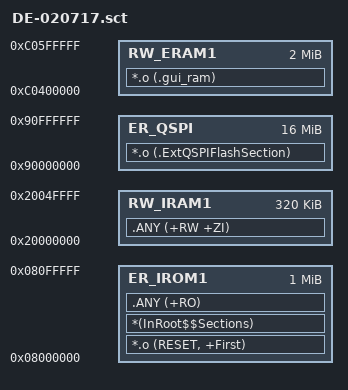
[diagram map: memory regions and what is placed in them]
; *************************************************************
; *** Scatter-Loading Description File generated by uVision ***
; *************************************************************

LR_IROM1 0x08000000 0x00100000    		; load region size_region  
{
	ER_IROM1 0x08000000 0x00100000  	; load address = execution address  
	{
		*.o (RESET, +First)
		*(InRoot$$Sections)
		.ANY (+RO)
	}
	
	RW_IRAM1	0x20000000 0x00050000  	; RW data  
	{
		.ANY (+RW +ZI)
	}
	RW_ERAM1	0xC0400000 0x00200000  	; SDRAM (2M) the name is arbitrary
	{  
		*.o (.gui_ram)					; GUI ram 
	}
}

LR_QSPI 0x90000000 0x1000000 
{
	ER_QSPI 0x90000000 0x1000000 
	{
		*.o (.ExtQSPIFlashSection)
	}
} 
